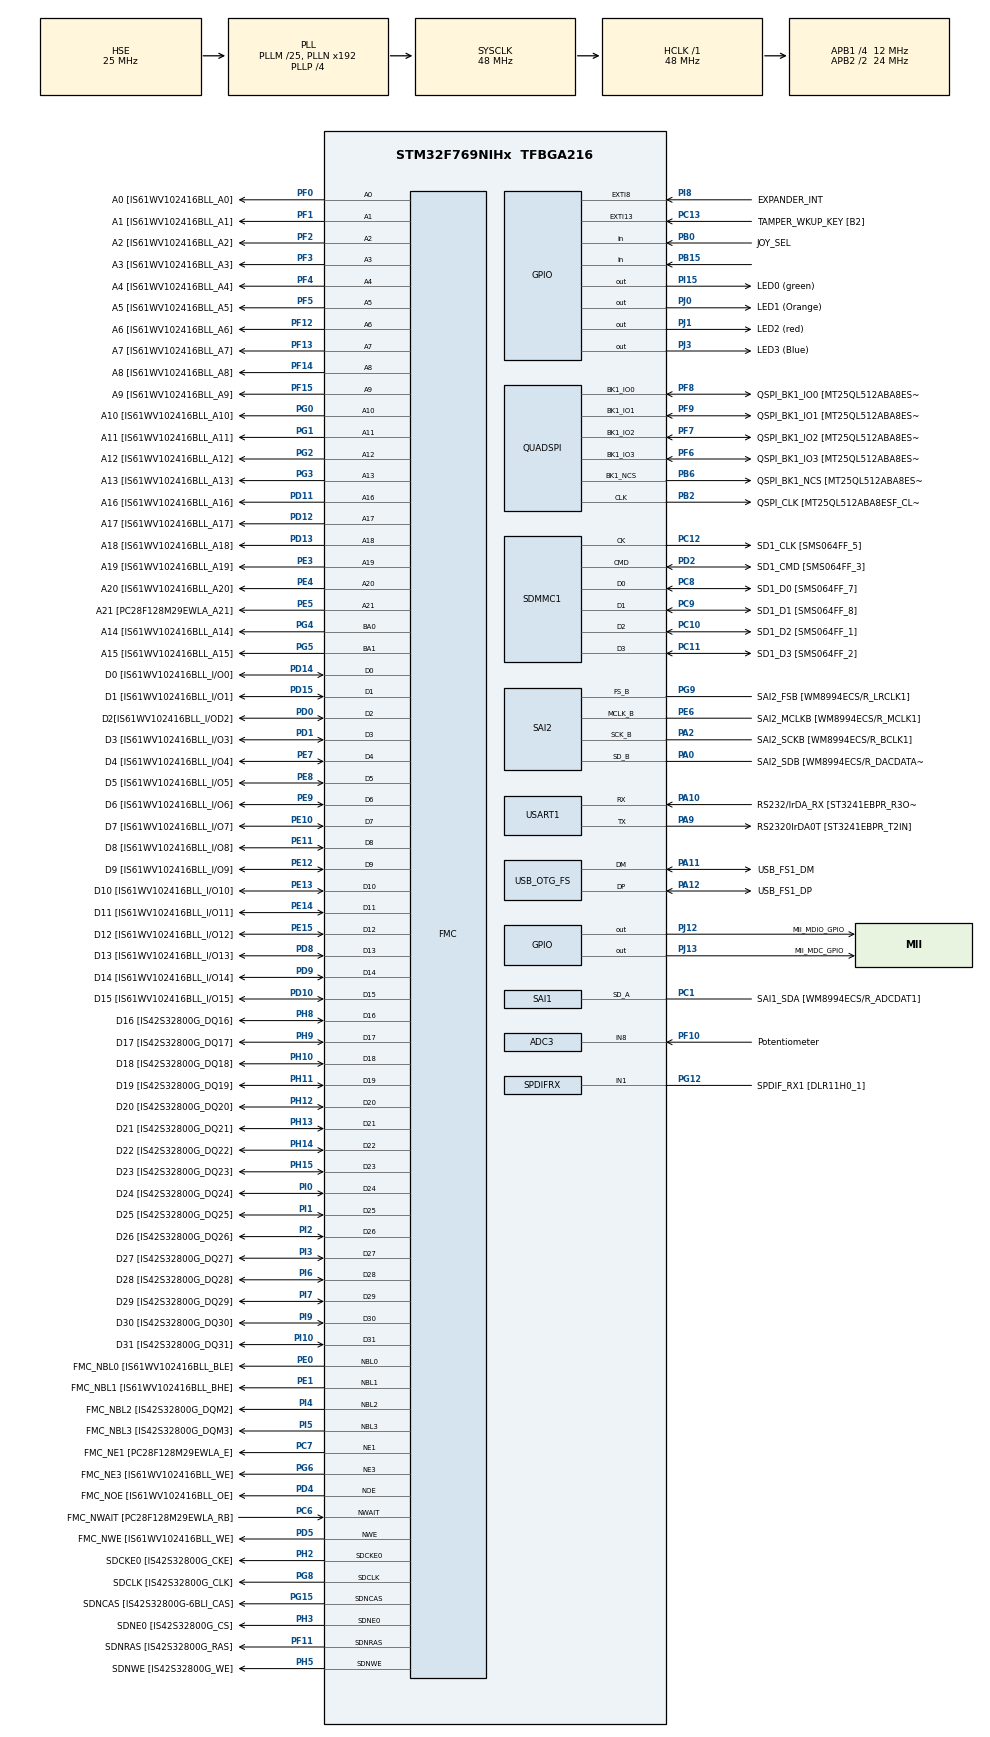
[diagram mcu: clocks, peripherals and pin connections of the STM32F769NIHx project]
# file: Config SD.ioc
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ADC3.Channel-0\#ChannelRegularConversion=ADC_CHANNEL_8
ADC3.NbrOfConversionFlag=1
ADC3.Rank-0\#ChannelRegularConversion=1
ADC3.SamplingTime-0\#ChannelRegularConversion=ADC_SAMPLETIME_3CYCLES
DSIHOST_CKN.GPIO_Label=DSI_CK_N
DSIHOST_CKN.Mode=DSIHost_Standalone
DSIHOST_CKN.Signal=DSIHOST_CKN
DSIHOST_CKP.GPIO_Label=DSI_CK_P
DSIHOST_CKP.Mode=DSIHost_Standalone
DSIHOST_CKP.Signal=DSIHOST_CKP
DSIHOST_D0N.GPIO_Label=DSI_D0_N
DSIHOST_D0N.Mode=DSIHost_Standalone
DSIHOST_D0N.Signal=DSIHOST_D0N
DSIHOST_D0P.GPIO_Label=DSI_D0_P
DSIHOST_D0P.Mode=DSIHost_Standalone
DSIHOST_D0P.Signal=DSIHOST_D0P
DSIHOST_D1N.GPIO_Label=DSI_D1_N
DSIHOST_D1N.Mode=DSIHost_Standalone
DSIHOST_D1N.Signal=DSIHOST_D1N
DSIHOST_D1P.GPIO_Label=DSI_D1_P
DSIHOST_D1P.Mode=DSIHost_Standalone
DSIHOST_D1P.Signal=DSIHOST_D1P
Dma.Request0=SDMMC1_RX
Dma.Request1=SDMMC1_TX
Dma.SDMMC1_RX.0.Direction=DMA_PERIPH_TO_MEMORY
Dma.SDMMC1_RX.0.FIFOMode=DMA_FIFOMODE_ENABLE
Dma.SDMMC1_RX.0.FIFOThreshold=DMA_FIFO_THRESHOLD_FULL
Dma.SDMMC1_RX.0.Instance=DMA2_Stream3
Dma.SDMMC1_RX.0.MemBurst=DMA_MBURST_INC4
Dma.SDMMC1_RX.0.MemDataAlignment=DMA_MDATAALIGN_WORD
Dma.SDMMC1_RX.0.MemInc=DMA_MINC_ENABLE
Dma.SDMMC1_RX.0.Mode=DMA_PFCTRL
Dma.SDMMC1_RX.0.PeriphBurst=DMA_PBURST_INC4
Dma.SDMMC1_RX.0.PeriphDataAlignment=DMA_PDATAALIGN_WORD
Dma.SDMMC1_RX.0.PeriphInc=DMA_PINC_DISABLE
Dma.SDMMC1_RX.0.Priority=DMA_PRIORITY_LOW
Dma.SDMMC1_TX.1.Direction=DMA_MEMORY_TO_PERIPH
Dma.SDMMC1_TX.1.FIFOMode=DMA_FIFOMODE_ENABLE
Dma.SDMMC1_TX.1.FIFOThreshold=DMA_FIFO_THRESHOLD_FULL
Dma.SDMMC1_TX.1.Instance=DMA2_Stream6
Dma.SDMMC1_TX.1.MemBurst=DMA_MBURST_INC4
Dma.SDMMC1_TX.1.MemDataAlignment=DMA_MDATAALIGN_WORD
Dma.SDMMC1_TX.1.MemInc=DMA_MINC_ENABLE
Dma.SDMMC1_TX.1.Mode=DMA_PFCTRL
Dma.SDMMC1_TX.1.PeriphBurst=DMA_PBURST_INC4
Dma.SDMMC1_TX.1.PeriphDataAlignment=DMA_PDATAALIGN_WORD
Dma.SDMMC1_TX.1.PeriphInc=DMA_PINC_DISABLE
Dma.SDMMC1_TX.1.Priority=DMA_PRIORITY_LOW
FATFS.BSP.number=1
FATFS.USE_DMA_CODE_SD=1
FATFS0.BSP.STBoard=false
FATFS0.BSP.api=Unknown
FATFS0.BSP.instance=PB15
FATFS0.BSP.ip=GPIO
FATFS0.BSP.mode=Input
FATFS0.BSP.name=Detect_SDIO
FATFS0.BSP.solution=PB15
Mcu.Family=STM32F7
Mcu.Name=STM32F769NIHx
Mcu.Package=TFBGA216
NVIC.DMA2_Stream3_IRQn=true\:0\:0\:false\:false\:true\:false\:true\:true
NVIC.DMA2_Stream6_IRQn=true\:0\:0\:false\:false\:true\:false\:true\:true
NVIC.PriorityGroup=NVIC_PRIORITYGROUP_4
NVIC.SDMMC1_IRQn=true\:0\:0\:false\:false\:true\:true\:true\:true
PA0/WKUP.GPIO_Label=SAI2_SDB [WM8994ECS/R_DACDATA1]
PA0/WKUP.Mode=SAI_B_MasterWithClock
PA0/WKUP.Signal=SAI2_SD_B
PA1.GPIO_Label=MII_RX_CLK [DP83848CVV_RX_CLK]
PA1.Signal=ETH_RX_CLK
PA10.GPIO_Label=RS232/IrDA_RX [ST3241EBPR_R3OUT]
PA10.Mode=Asynchronous
PA10.Signal=USART1_RX
PA11.GPIO_Label=USB_FS1_DM
PA11.Mode=Device_Only
PA11.Signal=USB_OTG_FS_DM
PA12.GPIO_Label=USB_FS1_DP
PA12.Mode=Device_Only
PA12.Signal=USB_OTG_FS_DP
PA13.GPIO_Label=TMS/SWDIO
PA13.Mode=Serial_Wire
PA13.Signal=SYS_JTMS-SWDIO
PA14.GPIO_Label=TCK/SWCLK
PA14.Mode=Serial_Wire
PA14.Signal=SYS_JTCK-SWCLK
PA15.GPIO_Label=TDI
PA15.Signal=SYS_JTDI
PA2.GPIO_Label=SAI2_SCKB [WM8994ECS/R_BCLK1]
PA2.Mode=SAI_B_MasterWithClock
PA2.Signal=SAI2_SCK_B
PA3.GPIO_Label=ULPI_D0 [USB3300-EZK_D0]
PA3.Signal=USB_OTG_HS_ULPI_D0
PA4.GPIO_Label=PAR_HSYNC
PA4.Signal=DCMI_HSYNC
PA5.GPIO_Label=ULPI_CK [USB3300-EZK_CLKOUT]
PA5.Signal=USB_OTG_HS_ULPI_CK
PA6.GPIO_Label=PAR_PCLK
PA6.Signal=DCMI_PIXCLK
PA7.GPIO_Label=MII_RX_DV [DP83848CVV_RX_DV]
PA7.Signal=ETH_RX_DV
PA8.GPIO_Label=MII_MCO [DP83848CVV_X1]
PA8.Signal=RCC_MCO_1
PA9.GPIO_Label=RS2320IrDA0T [ST3241EBPR_T2IN]
PA9.Mode=Asynchronous
PA9.Signal=USART1_TX
PB0.GPIO_Label=JOY_SEL
PB0.Signal=GPIO_Input
PB1.GPIO_Label=ULPI_D2 [USB3300-EZK_D2]
PB1.Signal=USB_OTG_HS_ULPI_D2
PB10.GPIO_Label=ULPI_D3 [USB3300-EZK_D3]
PB10.Signal=USB_OTG_HS_ULPI_D3
PB11.GPIO_Label=ULPI_D4 [USB3300-EZK_D4]
PB11.Signal=USB_OTG_HS_ULPI_D4
PB12.GPIO_Label=ULPI_D5 [USB3300-EZK_D5]
PB12.Signal=USB_OTG_HS_ULPI_D5
PB13.GPIO_Label=ULPI_D6 [USB3300-EZK_D6]
PB13.Signal=USB_OTG_HS_ULPI_D6
PB14.GPIO_Label=USB_FS2_DM
PB14.Signal=USB_OTG_HS_DM
PB15.Signal=GPIO_Input
PB2.GPIO_Label=QSPI_CLK [MT25QL512ABA8ESF_CLK]
PB2.Mode=Single Bank 1
PB2.Signal=QUADSPI_CLK
PB3.GPIO_Label=SD2_D2 [SMS064FF_1]
PB3.Signal=SDMMC2_D2
PB4.GPIO_Label=SD2_D3 [SMS064FF_2]
PB4.Signal=SDMMC2_D3
PB5.GPIO_Label=ULPI_D7 [USB3300-EZK_D7]
PB5.Signal=USB_OTG_HS_ULPI_D7
PB6.GPIO_Label=QSPI_BK1_NCS [MT25QL512ABA8ESF-0SIT_CS]
PB6.Mode=Single Bank 1
PB6.Signal=QUADSPI_BK1_NCS
PB7.GPIO_Label=PAR_VSYNC
PB7.Signal=DCMI_VSYNC
PB8.GPIO_Label=I2C1_SCL [WM8994ECS/R_SCLK]
PB8.Signal=I2C1_SCL
PB9.GPIO_Label=I2C1_SDA [WM8994ECS/R_SDA]
PB9.Signal=I2C1_SDA
PC0.GPIO_Label=ULPI_STP [USB3300-EZK_STP]
PC0.Signal=USB_OTG_HS_ULPI_STP
PC1.GPIO_Label=SAI1_SDA [WM8994ECS/R_ADCDAT1]
PC1.Mode=SAI_A_SPDIF
PC1.Signal=SAI1_SD_A
PC10.GPIO_Label=SD1_D2 [SMS064FF_1]
PC10.Mode=SD_4_bits_Wide_bus
PC10.Signal=SDMMC1_D2
PC11.GPIO_Label=SD1_D3 [SMS064FF_2]
PC11.Mode=SD_4_bits_Wide_bus
PC11.Signal=SDMMC1_D3
PC12.GPIO_Label=SD1_CLK [SMS064FF_5]
PC12.Mode=SD_4_bits_Wide_bus
PC12.Signal=SDMMC1_CK
PC13.GPIO_Label=TAMPER_WKUP_KEY [B2]
PC13.Signal=GPXTI13
PC14/OSC32_IN.GPIO_Label=OSC32_IN
PC14/OSC32_IN.Mode=LSE-External-Oscillator
PC14/OSC32_IN.Signal=RCC_OSC32_IN
PC15/OSC32_OUT.GPIO_Label=OSC32_OUT
PC15/OSC32_OUT.Mode=LSE-External-Oscillator
PC15/OSC32_OUT.Signal=RCC_OSC32_OUT
PC2.GPIO_Label=MII_TXD2 [DP83848CVV_TXD_2]
PC2.Signal=ETH_TXD2
PC3.GPIO_Label=MII_TX_CLK [DP83848CVV_TX_CLK]
PC3.Signal=ETH_TX_CLK
PC4.GPIO_Label=MII_RXD0 [DP83848CVV_RXD_0/PHYAD1]
PC4.Signal=ETH_RXD0
PC5.GPIO_Label=MII_RXD1 [DP83848CVV_RXD_1/PHYAD2]
PC5.Signal=ETH_RXD1
PC6.GPIO_Label=FMC_NWAIT [PC28F128M29EWLA_RB]
PC6.Signal=FMC_NWAIT
PC7.GPIO_Label=FMC_NE1 [PC28F128M29EWLA_E]
PC7.Mode=NorPsramChipSelect1_1
PC7.Signal=FMC_NE1
PC8.GPIO_Label=SD1_D0 [SMS064FF_7]
PC8.Mode=SD_4_bits_Wide_bus
PC8.Signal=SDMMC1_D0
PC9.GPIO_Label=SD1_D1 [SMS064FF_8]
PC9.Mode=SD_4_bits_Wide_bus
PC9.Signal=SDMMC1_D1
PD0.GPIO_Label=D2[IS61WV102416BLL_I/OD2]
PD0.Signal=FMC_D2_DA2
PD1.GPIO_Label=D3 [IS61WV102416BLL_I/O3]
PD1.Signal=FMC_D3_DA3
PD10.GPIO_Label=D15 [IS61WV102416BLL_I/O15]
PD10.Signal=FMC_D15_DA15
PD11.GPIO_Label=A16 [IS61WV102416BLL_A16]
PD11.Signal=FMC_A16_CLE
PD12.GPIO_Label=A17 [IS61WV102416BLL_A17]
PD12.Signal=FMC_A17_ALE
PD13.GPIO_Label=A18 [IS61WV102416BLL_A18]
PD13.Signal=FMC_A18
PD14.GPIO_Label=D0 [IS61WV102416BLL_I/O0]
PD14.Signal=FMC_D0_DA0
PD15.GPIO_Label=D1 [IS61WV102416BLL_I/O1]
PD15.Signal=FMC_D1_DA1
PD2.GPIO_Label=SD1_CMD [SMS064FF_3]
PD2.Mode=SD_4_bits_Wide_bus
PD2.Signal=SDMMC1_CMD
PD3.GPIO_Label=PAR_D5
PD3.Signal=DCMI_D5
PD4.GPIO_Label=FMC_NOE [IS61WV102416BLL_OE]
PD4.Signal=FMC_NOE
PD5.GPIO_Label=FMC_NWE [IS61WV102416BLL_WE]
PD5.Signal=FMC_NWE
PD6.GPIO_Label=SD2_CLK [SMS064FF_5]
PD6.Signal=SDMMC2_CK
PD7.GPIO_Label=SD2_CMD [SMS064FF_3]
PD7.Signal=SDMMC2_CMD
PD8.GPIO_Label=D13 [IS61WV102416BLL_I/O13]
PD8.Signal=FMC_D13_DA13
PD9.GPIO_Label=D14 [IS61WV102416BLL_I/O14]
PD9.Signal=FMC_D14_DA14
PE0.GPIO_Label=FMC_NBL0 [IS61WV102416BLL_BLE]
PE0.Signal=FMC_NBL0
PE1.GPIO_Label=FMC_NBL1 [IS61WV102416BLL_BHE]
PE1.Signal=FMC_NBL1
PE10.GPIO_Label=D7 [IS61WV102416BLL_I/O7]
PE10.Signal=FMC_D7_DA7
PE11.GPIO_Label=D8 [IS61WV102416BLL_I/O8]
PE11.Signal=FMC_D8_DA8
PE12.GPIO_Label=D9 [IS61WV102416BLL_I/O9]
PE12.Signal=FMC_D9_DA9
PE13.GPIO_Label=D10 [IS61WV102416BLL_I/O10]
PE13.Signal=FMC_D10_DA10
PE14.GPIO_Label=D11 [IS61WV102416BLL_I/O11]
PE14.Signal=FMC_D11_DA11
PE15.GPIO_Label=D12 [IS61WV102416BLL_I/O12]
PE15.Signal=FMC_D12_DA12
PE2.GPIO_Label=MII_TXD3 [DP83848CVV_TXD_3]
PE2.Signal=ETH_TXD3
PE3.GPIO_Label=A19 [IS61WV102416BLL_A19]
PE3.Signal=FMC_A19
PE4.GPIO_Label=A20 [IS61WV102416BLL_A20]
PE4.Signal=FMC_A20
PE5.GPIO_Label=A21 [PC28F128M29EWLA_A21]
PE5.Signal=FMC_A21
PE6.GPIO_Label=SAI2_MCLKB [WM8994ECS/R_MCLK1]
PE6.Mode=SAI_B_MasterWithClock
PE6.Signal=SAI2_MCLK_B
PE7.GPIO_Label=D4 [IS61WV102416BLL_I/O4]
PE7.Signal=FMC_D4_DA4
PE8.GPIO_Label=D5 [IS61WV102416BLL_I/O5]
PE8.Signal=FMC_D5_DA5
PE9.GPIO_Label=D6 [IS61WV102416BLL_I/O6]
PE9.Signal=FMC_D6_DA6
PF0.GPIO_Label=A0 [IS61WV102416BLL_A0]
PF0.Signal=FMC_A0
PF1.GPIO_Label=A1 [IS61WV102416BLL_A1]
PF1.Signal=FMC_A1
PF10.GPIO_Label=Potentiometer
PF10.Mode=IN8
PF10.Signal=ADC3_IN8
PF11.GPIO_Label=SDNRAS [IS42S32800G_RAS]
PF11.Signal=FMC_SDNRAS
PF12.GPIO_Label=A6 [IS61WV102416BLL_A6]
PF12.Signal=FMC_A6
PF13.GPIO_Label=A7 [IS61WV102416BLL_A7]
PF13.Signal=FMC_A7
PF14.GPIO_Label=A8 [IS61WV102416BLL_A8]
PF14.Signal=FMC_A8
PF15.GPIO_Label=A9 [IS61WV102416BLL_A9]
PF15.Signal=FMC_A9
PF2.GPIO_Label=A2 [IS61WV102416BLL_A2]
PF2.Signal=FMC_A2
PF3.GPIO_Label=A3 [IS61WV102416BLL_A3]
PF3.Signal=FMC_A3
PF4.GPIO_Label=A4 [IS61WV102416BLL_A4]
PF4.Signal=FMC_A4
PF5.GPIO_Label=A5 [IS61WV102416BLL_A5]
PF5.Signal=FMC_A5
PF6.GPIO_Label=QSPI_BK1_IO3 [MT25QL512ABA8ESF_HOLD\#/DQ3]
PF6.Mode=Single Bank 1
PF6.Signal=QUADSPI_BK1_IO3
PF7.GPIO_Label=QSPI_BK1_IO2 [MT25QL512ABA8ESF_W\#/Vpp/DQ2]
PF7.Mode=Single Bank 1
PF7.Signal=QUADSPI_BK1_IO2
PF8.GPIO_Label=QSPI_BK1_IO0 [MT25QL512ABA8ESF_DQ0]
PF8.Mode=Single Bank 1
PF8.Signal=QUADSPI_BK1_IO0
PF9.GPIO_Label=QSPI_BK1_IO1 [MT25QL512ABA8ESF_DQ1]
PF9.Mode=Single Bank 1
PF9.Signal=QUADSPI_BK1_IO1
PG0.GPIO_Label=A10 [IS61WV102416BLL_A10]
PG0.Signal=FMC_A10
PG1.GPIO_Label=A11 [IS61WV102416BLL_A11]
PG1.Signal=FMC_A11
PG10.GPIO_Label=SD2_D1 [SMS064FF_8]
PG10.Signal=SDMMC2_D1
PG11.GPIO_Label=MII_TX_EN [DP83848CVV_TX_EN]
PG11.Signal=ETH_TX_EN
PG12.GPIO_Label=SPDIF_RX1 [DLR11H0_1]
PG12.Mode=IN1
PG12.Signal=SPDIFRX_IN1
PG13.GPIO_Label=MII_TXD0 [DP83848CVV_TXD0]
PG13.Signal=ETH_TXD0
PG14.GPIO_Label=MII_TXD1 [DP83848CVV_TXD1]
PG14.Signal=ETH_TXD1
PG15.GPIO_Label=SDNCAS [IS42S32800G-6BLI_CAS]
PG15.Signal=FMC_SDNCAS
PG2.GPIO_Label=A12 [IS61WV102416BLL_A12]
PG2.Signal=FMC_A12
PG3.GPIO_Label=A13 [IS61WV102416BLL_A13]
PG3.Signal=FMC_A13
PG4.GPIO_Label=A14 [IS61WV102416BLL_A14]
PG4.Signal=FMC_A14_BA0
PG5.GPIO_Label=A15 [IS61WV102416BLL_A15]
PG5.Signal=FMC_A15_BA1
PG6.GPIO_Label=FMC_NE3 [IS61WV102416BLL_WE]
PG6.Mode=NorPsramChipSelect3_2
PG6.Signal=FMC_NE3
PG7.GPIO_Label=NAND_INT
PG7.Signal=FMC_INT
PG8.GPIO_Label=SDCLK [IS42S32800G_CLK]
PG8.Signal=FMC_SDCLK
PG9.GPIO_Label=SAI2_FSB [WM8994ECS/R_LRCLK1]
PG9.Mode=SAI_B_MasterWithClock
PG9.Signal=SAI2_FS_B
PH0/OSC_IN.GPIO_Label=OSC_IN
PH0/OSC_IN.Mode=HSE-External-Oscillator
PH0/OSC_IN.Signal=RCC_OSC_IN
PH1/OSC_OUT.GPIO_Label=OSC_OUT
PH1/OSC_OUT.Mode=HSE-External-Oscillator
PH1/OSC_OUT.Signal=RCC_OSC_OUT
PH10.GPIO_Label=D18 [IS42S32800G_DQ18]
PH10.Signal=FMC_D18
PH11.GPIO_Label=D19 [IS42S32800G_DQ19]
PH11.Signal=FMC_D19
PH12.GPIO_Label=D20 [IS42S32800G_DQ20]
PH12.Signal=FMC_D20
PH13.GPIO_Label=D21 [IS42S32800G_DQ21]
PH13.Signal=FMC_D21
PH14.GPIO_Label=D22 [IS42S32800G_DQ22]
PH14.Signal=FMC_D22
PH15.GPIO_Label=D23 [IS42S32800G_DQ23]
PH15.Signal=FMC_D23
PH2.GPIO_Label=SDCKE0 [IS42S32800G_CKE]
PH2.Mode=SdramChipSelect1_1
PH2.Signal=FMC_SDCKE0
PH3.GPIO_Label=SDNE0 [IS42S32800G_CS]
PH3.Mode=SdramChipSelect1_1
PH3.Signal=FMC_SDNE0
PH4.GPIO_Label=ULPI_NXT [USB3300-EZK_NXT]
PH4.Signal=USB_OTG_HS_ULPI_NXT
PH5.GPIO_Label=SDNWE [IS42S32800G_WE]
PH5.Signal=FMC_SDNWE
PH6.GPIO_Label=MII_RXD2 [DP83848CVV_RXD_2/PHYAD3]
PH6.Signal=ETH_RXD2
PH7.GPIO_Label=MII_RXD3 [DP83848CVV_RXD_3/PHYAD4]
PH7.Signal=ETH_RXD3
PH8.GPIO_Label=D16 [IS42S32800G_DQ16]
PH8.Signal=FMC_D16
PH9.GPIO_Label=D17 [IS42S32800G_DQ17]
PH9.Signal=FMC_D17
PI0.GPIO_Label=D24 [IS42S32800G_DQ24]
PI0.Signal=FMC_D24
PI1.GPIO_Label=D25 [IS42S32800G_DQ25]
PI1.Signal=FMC_D25
PI10.GPIO_Label=D31 [IS42S32800G_DQ31]
PI10.Signal=FMC_D31
PI11.GPIO_Label=ULPI_DIR [USB3300_DIR]
PI11.Signal=USB_OTG_HS_ULPI_DIR
PI12.GPIO_Label=LCD_HSYNC
PI12.Signal=LTDC_HSYNC
PI13.GPIO_Label=LCD_VSYNC
PI13.Signal=LTDC_VSYNC
PI14.GPIO_Label=LCD_CLK
PI14.Signal=LTDC_CLK
PI15.GPIO_Label=LED0 (green)
PI15.Signal=GPIO_Output
PI2.GPIO_Label=D26 [IS42S32800G_DQ26]
PI2.Signal=FMC_D26
PI3.GPIO_Label=D27 [IS42S32800G_DQ27]
PI3.Signal=FMC_D27
PI4.GPIO_Label=FMC_NBL2 [IS42S32800G_DQM2]
PI4.Signal=FMC_NBL2
PI5.GPIO_Label=FMC_NBL3 [IS42S32800G_DQM3]
PI5.Signal=FMC_NBL3
PI6.GPIO_Label=D28 [IS42S32800G_DQ28]
PI6.Signal=FMC_D28
PI7.GPIO_Label=D29 [IS42S32800G_DQ29]
PI7.Signal=FMC_D29
PI8.GPIO_Label=EXPANDER_INT
PI8.Signal=GPXTI8
PI9.GPIO_Label=D30 [IS42S32800G_DQ30]
PI9.Signal=FMC_D30
PJ0.GPIO_Label=LED1 (Orange)
PJ0.Signal=GPIO_Output
PJ1.GPIO_Label=LED2 (red)
PJ1.Signal=GPIO_Output
PJ12.GPIO_Label=MII_MDIO_GPIO
PJ12.Signal=GPIO_Output
PJ13.GPIO_Label=MII_MDC_GPIO
PJ13.Signal=GPIO_Output
PJ14.GPIO_Label=LCD_B2
PJ14.Signal=LTDC_B2
PJ15.GPIO_Label=LCD_B3
PJ15.Signal=LTDC_B3
PJ2.GPIO_Label=DSI_TE
PJ2.Signal=DSIHOST_TE
PJ3.GPIO_Label=LED3 (Blue)
PJ3.Signal=GPIO_Output
PJ4.GPIO_Label=LCD_R5
PJ4.Signal=LTDC_R5
PJ5.GPIO_Label=LCD_R6
PJ5.Signal=LTDC_R6
PK3.GPIO_Label=LCD_B4
PK3.Signal=LTDC_B4
PK4.GPIO_Label=LCD_B5
PK4.Signal=LTDC_B5
PK5.GPIO_Label=LCD_B6
PK5.Signal=LTDC_B6
PK6.GPIO_Label=LCD_B7
PK6.Signal=LTDC_B7
PK7.GPIO_Label=LCD_DE
PK7.Signal=LTDC_DE
ProjectManager.HeapSize=0x400
ProjectManager.StackSize=0x800
ProjectManager.TargetToolchain=STM32CubeIDE
QUADSPI.ChipSelectHighTime=QSPI_CS_HIGH_TIME_6_CYCLE
QUADSPI.ClockPrescaler=1
QUADSPI.FifoThreshold=4
QUADSPI.FlashSize=26
QUADSPI.SampleShifting=QSPI_SAMPLE_SHIFTING_HALFCYCLE
RCC.AHBFreq_Value=48000000
RCC.APB1CLKDivider=RCC_HCLK_DIV4
RCC.APB1Freq_Value=12000000
RCC.APB1TimFreq_Value=24000000
RCC.APB2CLKDivider=RCC_HCLK_DIV2
RCC.APB2Freq_Value=24000000
RCC.APB2TimFreq_Value=48000000
RCC.CortexFreq_Value=48000000
RCC.HCLKFreq_Value=48000000
RCC.HSE_VALUE=25000000
RCC.HSI_VALUE=16000000
RCC.PLLM=25
RCC.PLLP=RCC_PLLP_DIV4
RCC.PLLQ=4
RCC.PLLSAIQ=3
RCC.SDMMCClockSelection=RCC_SDMMC1CLKSOURCE_CLK48
RCC.SYSCLKFreq_VALUE=48000000
RCC.SYSCLKSource=RCC_SYSCLKSOURCE_PLLCLK
RCC.USBFreq_Value=48000000
RCC.VCOOutputFreq_Value=192000000
SAI1.Instance-SAI_A_SPDIF=SAI$Index_Block_A
SAI1.VirtualMode-SAI_A_SPDIF=VM_SPDIF
SAI2.Instance-SAI_B_MasterWithClock=SAI$Index_Block_B
SAI2.MClockEnable-SAI_B_MasterWithClock=SAI_MASTERCLOCK_ENABLE
SAI2.VirtualMode-SAI_B_MasterWithClock=VM_MASTER
SH.FMC_A0.0=FMC_A0,13b-sda1
SH.FMC_A0.1=FMC_A0,22b-a1
SH.FMC_A0.2=FMC_A0,22b-a2
SH.FMC_A1.0=FMC_A1,13b-sda1
SH.FMC_A1.1=FMC_A1,22b-a1
SH.FMC_A1.2=FMC_A1,22b-a2
SH.FMC_A10.0=FMC_A10,13b-sda1
SH.FMC_A10.1=FMC_A10,22b-a1
SH.FMC_A10.2=FMC_A10,22b-a2
SH.FMC_A11.0=FMC_A11,13b-sda1
SH.FMC_A11.1=FMC_A11,22b-a1
SH.FMC_A11.2=FMC_A11,22b-a2
SH.FMC_A12.0=FMC_A12,13b-sda1
SH.FMC_A12.1=FMC_A12,22b-a1
SH.FMC_A12.2=FMC_A12,22b-a2
SH.FMC_A13.0=FMC_A13,22b-a1
SH.FMC_A13.1=FMC_A13,22b-a2
SH.FMC_A14_BA0.0=FMC_BA0,FourSdramBanks1
SH.FMC_A14_BA0.1=FMC_A14,22b-a1
SH.FMC_A14_BA0.2=FMC_A14,22b-a2
SH.FMC_A15_BA1.0=FMC_BA1,FourSdramBanks1
SH.FMC_A15_BA1.1=FMC_A15,22b-a1
SH.FMC_A15_BA1.2=FMC_A15,22b-a2
SH.FMC_A16_CLE.0=FMC_A16,22b-a1
SH.FMC_A16_CLE.1=FMC_A16,22b-a2
SH.FMC_A17_ALE.0=FMC_A17,22b-a1
SH.FMC_A17_ALE.1=FMC_A17,22b-a2
SH.FMC_A18.0=FMC_A18,22b-a1
SH.FMC_A18.1=FMC_A18,22b-a2
SH.FMC_A19.0=FMC_A19,22b-a1
SH.FMC_A19.1=FMC_A19,22b-a2
SH.FMC_A2.0=FMC_A2,13b-sda1
SH.FMC_A2.1=FMC_A2,22b-a1
SH.FMC_A2.2=FMC_A2,22b-a2
SH.FMC_A20.0=FMC_A20,22b-a1
SH.FMC_A20.1=FMC_A20,22b-a2
SH.FMC_A21.0=FMC_A21,22b-a1
SH.FMC_A21.1=FMC_A21,22b-a2
SH.FMC_A3.0=FMC_A3,13b-sda1
SH.FMC_A3.1=FMC_A3,22b-a1
SH.FMC_A3.2=FMC_A3,22b-a2
SH.FMC_A4.0=FMC_A4,13b-sda1
SH.FMC_A4.1=FMC_A4,22b-a1
SH.FMC_A4.2=FMC_A4,22b-a2
SH.FMC_A5.0=FMC_A5,13b-sda1
SH.FMC_A5.1=FMC_A5,22b-a1
SH.FMC_A5.2=FMC_A5,22b-a2
SH.FMC_A6.0=FMC_A6,13b-sda1
SH.FMC_A6.1=FMC_A6,22b-a1
SH.FMC_A6.2=FMC_A6,22b-a2
SH.FMC_A7.0=FMC_A7,13b-sda1
SH.FMC_A7.1=FMC_A7,22b-a1
SH.FMC_A7.2=FMC_A7,22b-a2
SH.FMC_A8.0=FMC_A8,13b-sda1
SH.FMC_A8.1=FMC_A8,22b-a1
SH.FMC_A8.2=FMC_A8,22b-a2
SH.FMC_A9.0=FMC_A9,13b-sda1
SH.FMC_A9.1=FMC_A9,22b-a1
SH.FMC_A9.2=FMC_A9,22b-a2
SH.FMC_D0_DA0.0=FMC_D0,16b-d1
SH.FMC_D0_DA0.1=FMC_D0,16b-d2
SH.FMC_D0_DA0.2=FMC_D0,sd-32b-d1
SH.FMC_D10_DA10.0=FMC_D10,16b-d1
SH.FMC_D10_DA10.1=FMC_D10,16b-d2
SH.FMC_D10_DA10.2=FMC_D10,sd-32b-d1
SH.FMC_D11_DA11.0=FMC_D11,16b-d1
SH.FMC_D11_DA11.1=FMC_D11,16b-d2
SH.FMC_D11_DA11.2=FMC_D11,sd-32b-d1
SH.FMC_D12_DA12.0=FMC_D12,16b-d1
SH.FMC_D12_DA12.1=FMC_D12,16b-d2
SH.FMC_D12_DA12.2=FMC_D12,sd-32b-d1
SH.FMC_D13_DA13.0=FMC_D13,16b-d1
SH.FMC_D13_DA13.1=FMC_D13,16b-d2
SH.FMC_D13_DA13.2=FMC_D13,sd-32b-d1
SH.FMC_D14_DA14.0=FMC_D14,16b-d1
SH.FMC_D14_DA14.1=FMC_D14,16b-d2
SH.FMC_D14_DA14.2=FMC_D14,sd-32b-d1
SH.FMC_D15_DA15.0=FMC_D15,16b-d1
SH.FMC_D15_DA15.1=FMC_D15,16b-d2
SH.FMC_D15_DA15.2=FMC_D15,sd-32b-d1
SH.FMC_D16.0=FMC_D16,sd-32b-d1
SH.FMC_D17.0=FMC_D17,sd-32b-d1
SH.FMC_D18.0=FMC_D18,sd-32b-d1
SH.FMC_D19.0=FMC_D19,sd-32b-d1
SH.FMC_D1_DA1.0=FMC_D1,16b-d1
SH.FMC_D1_DA1.1=FMC_D1,16b-d2
SH.FMC_D1_DA1.2=FMC_D1,sd-32b-d1
SH.FMC_D20.0=FMC_D20,sd-32b-d1
SH.FMC_D21.0=FMC_D21,sd-32b-d1
SH.FMC_D22.0=FMC_D22,sd-32b-d1
SH.FMC_D23.0=FMC_D23,sd-32b-d1
SH.FMC_D24.0=FMC_D24,sd-32b-d1
SH.FMC_D25.0=FMC_D25,sd-32b-d1
SH.FMC_D26.0=FMC_D26,sd-32b-d1
SH.FMC_D27.0=FMC_D27,sd-32b-d1
SH.FMC_D28.0=FMC_D28,sd-32b-d1
SH.FMC_D29.0=FMC_D29,sd-32b-d1
SH.FMC_D2_DA2.0=FMC_D2,16b-d1
SH.FMC_D2_DA2.1=FMC_D2,16b-d2
SH.FMC_D2_DA2.2=FMC_D2,sd-32b-d1
SH.FMC_D30.0=FMC_D30,sd-32b-d1
SH.FMC_D31.0=FMC_D31,sd-32b-d1
SH.FMC_D3_DA3.0=FMC_D3,16b-d1
SH.FMC_D3_DA3.1=FMC_D3,16b-d2
SH.FMC_D3_DA3.2=FMC_D3,sd-32b-d1
SH.FMC_D4_DA4.0=FMC_D4,16b-d1
SH.FMC_D4_DA4.1=FMC_D4,16b-d2
SH.FMC_D4_DA4.2=FMC_D4,sd-32b-d1
SH.FMC_D5_DA5.0=FMC_D5,16b-d1
SH.FMC_D5_DA5.1=FMC_D5,16b-d2
SH.FMC_D5_DA5.2=FMC_D5,sd-32b-d1
SH.FMC_D6_DA6.0=FMC_D6,16b-d1
SH.FMC_D6_DA6.1=FMC_D6,16b-d2
SH.FMC_D6_DA6.2=FMC_D6,sd-32b-d1
SH.FMC_D7_DA7.0=FMC_D7,16b-d1
SH.FMC_D7_DA7.1=FMC_D7,16b-d2
SH.FMC_D7_DA7.2=FMC_D7,sd-32b-d1
SH.FMC_D8_DA8.0=FMC_D8,16b-d1
SH.FMC_D8_DA8.1=FMC_D8,16b-d2
SH.FMC_D8_DA8.2=FMC_D8,sd-32b-d1
SH.FMC_D9_DA9.0=FMC_D9,16b-d1
SH.FMC_D9_DA9.1=FMC_D9,16b-d2
SH.FMC_D9_DA9.2=FMC_D9,sd-32b-d1
SH.FMC_INT.0=FMC_INT
SH.FMC_NBL0.0=FMC_NBL0,2ByteEnable2
SH.FMC_NBL0.1=FMC_NBL0,Sd4ByteEnable1
SH.FMC_NBL1.0=FMC_NBL1,2ByteEnable2
SH.FMC_NBL1.1=FMC_NBL1,Sd4ByteEnable1
SH.FMC_NBL2.0=FMC_NBL2,Sd4ByteEnable1
SH.FMC_NBL3.0=FMC_NBL3,Sd4ByteEnable1
SH.FMC_NOE.0=FMC_NOE,NorFlash1
SH.FMC_NOE.1=FMC_NOE,Sram2
SH.FMC_NWAIT.0=FMC_NWAIT,AsynchronousWait1
SH.FMC_NWAIT.1=FMC_NWAIT,AsynchronousWait2
SH.FMC_NWE.0=FMC_NWE,NorFlash1
SH.FMC_NWE.1=FMC_NWE,Sram2
SH.FMC_SDCLK.0=FMC_SDCLK,13b-sda1
SH.FMC_SDNCAS.0=FMC_SDNCAS,13b-sda1
SH.FMC_SDNRAS.0=FMC_SDNRAS,13b-sda1
SH.FMC_SDNWE.0=FMC_SDNWE,13b-sda1
USART1.VirtualMode-Asynchronous=VM_ASYNC
USB_OTG_FS.VirtualMode=Device_Only
VP_FATFS_VS_SDIO.Mode=SDIO
VP_RTC_VS_RTC_Activate.Mode=RTC_Enabled
VP_RTC_VS_RTC_Calendar.Mode=RTC_Calendar
board=STM32F769I-EVAL

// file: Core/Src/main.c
/* USER CODE BEGIN Header */
/**
  ******************************************************************************
  * @file           : main.c
  * @brief          : Main program body
  ******************************************************************************
  * @attention
  *
  * Copyright (c) 2022 STMicroelectronics.
  * All rights reserved.
  *
  * This software is licensed under terms that can be found in the LICENSE file
  * in the root directory of this software component.
  * If no LICENSE file comes with this software, it is provided AS-IS.
  *
  ******************************************************************************
  */
/* USER CODE END Header */
#include "main.h"
#include "fatfs.h"

/* USER CODE BEGIN Includes */
#include <stdio.h>
//define flag rtc
#define SET_TIME_RTC 0
//string to date config

/* USER CODE END Includes */

ADC_HandleTypeDef hadc3;

DSI_HandleTypeDef hdsi;

QSPI_HandleTypeDef hqspi;

RTC_HandleTypeDef hrtc;

SAI_HandleTypeDef hsai_BlockA1;
SAI_HandleTypeDef hsai_BlockB2;

SD_HandleTypeDef hsd1;
DMA_HandleTypeDef hdma_sdmmc1_rx;
DMA_HandleTypeDef hdma_sdmmc1_tx;

SPDIFRX_HandleTypeDef hspdif;

UART_HandleTypeDef huart1;

PCD_HandleTypeDef hpcd_USB_OTG_FS;

NOR_HandleTypeDef hnor1;
SRAM_HandleTypeDef hsram2;
SDRAM_HandleTypeDef hsdram1;

void SystemClock_Config(void);
void PeriphCommonClock_Config(void);
static void MX_GPIO_Init(void);
static void MX_ADC3_Init(void);
static void MX_DSIHOST_DSI_Init(void);
static void MX_FMC_Init(void);
static void MX_QUADSPI_Init(void);
static void MX_SAI1_Init(void);
static void MX_SAI2_Init(void);
static void MX_SDMMC1_SD_Init(void);
static void MX_SPDIFRX_Init(void);
static void MX_USART1_UART_Init(void);
static void MX_USB_OTG_FS_PCD_Init(void);
static void MX_DMA_Init(void);
static void MX_RTC_Init(void);

/* USER CODE BEGIN 0 */
char* time, date;

void get_time(void)
{
 RTC_DateTypeDef gDate;
 RTC_TimeTypeDef gTime;
/* Get the RTC current Time */
 HAL_RTC_GetTime(&hrtc, &gTime, RTC_FORMAT_BIN);
/* Get the RTC current Date */
 HAL_RTC_GetDate(&hrtc, &gDate, RTC_FORMAT_BIN);
/* Display time Format: hh:mm:ss */
 sprintf((char*)time,"%02d:%02d:%02d",gTime.Hours, gTime.Minutes, gTime.Seconds);
/* Display date Format: dd-mm-yy */
 sprintf((char*)date,"%02d-%02d-%4d",gDate.Date, gDate.Month, 2000 + gDate.Year);

}
/* USER CODE END 0 */

int main(void)
{
  /* USER CODE BEGIN 1 */
  FRESULT res; /* FatFs function common result code */
  uint32_t byteswritten, bytesread; /* File write/read counts */
  uint8_t wtext[] = "STM32 FATFS works great!"; /* File write buffer */
  uint8_t rtext[_MAX_SS];/* File read buffer */

  /* USER CODE END 1 */

  /* MCU Configuration--------------------------------------------------------*/

  /* Reset of all peripherals, Initializes the Flash interface and the Systick. */
  HAL_Init();

  /* Configure the system clock */
  SystemClock_Config();

/* Configure the peripherals common clocks */
  PeriphCommonClock_Config();

  /* Initialize all configured peripherals */
  MX_GPIO_Init();
  MX_ADC3_Init();
  MX_DSIHOST_DSI_Init();
  MX_FMC_Init();
  MX_QUADSPI_Init();
  MX_SAI1_Init();
  MX_SAI2_Init();
  MX_SDMMC1_SD_Init();
  MX_SPDIFRX_Init();
  MX_USART1_UART_Init();
  MX_USB_OTG_FS_PCD_Init();
  MX_DMA_Init();
  MX_RTC_Init();
  MX_FATFS_Init();
  /* USER CODE BEGIN 2 */
  HAL_GPIO_WritePin(LED0_GPIO_Port, LED0_Pin, GPIO_PIN_SET);
  HAL_GPIO_WritePin(LED1_GPIO_Port, LED1_Pin, GPIO_PIN_SET);
  HAL_GPIO_WritePin(LED2_GPIO_Port, LED2_Pin, GPIO_PIN_SET);
  HAL_GPIO_WritePin(LED3_GPIO_Port, LED3_Pin, GPIO_PIN_SET);
  if(f_mount(&SDFatFS, (TCHAR const*)SDPath, 0) != FR_OK)
      {
	  HAL_GPIO_TogglePin(LED2_GPIO_Port, LED3_Pin);
          Error_Handler();
      }
      else
      {
          if(f_mkfs((TCHAR const*)SDPath, FM_ANY, 0, rtext, sizeof(rtext)) != FR_OK)
          {
        	  HAL_GPIO_TogglePin(LED2_GPIO_Port, LED3_Pin);
              Error_Handler();
          }
          else
          {
              //Open file for writing (Create)
              if(f_open(&SDFile, "STM32.TXT", FA_CREATE_ALWAYS | FA_WRITE) != FR_OK)
              {
            	  HAL_GPIO_TogglePin(LED2_GPIO_Port, LED3_Pin);
                  Error_Handler();
              }
              else
              {

                  //Write to the text file
                  res = f_write(&SDFile, time, strlen((char *)time), (void *)&byteswritten);
                  if((byteswritten == 0) || (res != FR_OK))
                  {
                	  HAL_GPIO_TogglePin(LED2_GPIO_Port, LED3_Pin);
                      Error_Handler();
                  }
                  else
                  {

                      f_close(&SDFile);
                  }
              }
          }
      }
      f_mount(&SDFatFS, (TCHAR const*)NULL, 0);

  /* USER CODE END 2 */

  /* Infinite loop */
  while (1)
  {

    /* USER CODE BEGIN 3 */
	  HAL_GPIO_TogglePin(LED2_GPIO_Port, LED2_Pin);
	  HAL_Delay(1000);
	  get_time();
	  if (HAL_GPIO_ReadPin(JOY_SEL_GPIO_Port, JOY_SEL_Pin) == 1)
		  HAL_GPIO_WritePin(LED0_GPIO_Port, LED0_Pin, GPIO_PIN_SET);
	  else
	  {
		  HAL_GPIO_WritePin(LED0_GPIO_Port, LED0_Pin, GPIO_PIN_RESET);
	  }
  }
  /* USER CODE END 3 */
}

void SystemClock_Config(void)
{
  RCC_OscInitTypeDef RCC_OscInitStruct = {0};
  RCC_ClkInitTypeDef RCC_ClkInitStruct = {0};

  /** Configure LSE Drive Capability
  */
  HAL_PWR_EnableBkUpAccess();

  /** Configure the main internal regulator output voltage
  */
  __HAL_RCC_PWR_CLK_ENABLE();
  __HAL_PWR_VOLTAGESCALING_CONFIG(PWR_REGULATOR_VOLTAGE_SCALE3);

  /** Initializes the RCC Oscillators according to the specified parameters
  * in the RCC_OscInitTypeDef structure.
  */
  RCC_OscInitStruct.OscillatorType = RCC_OSCILLATORTYPE_LSI|RCC_OSCILLATORTYPE_HSE;
  RCC_OscInitStruct.HSEState = RCC_HSE_ON;
  RCC_OscInitStruct.LSIState = RCC_LSI_ON;
  RCC_OscInitStruct.PLL.PLLState = RCC_PLL_ON;
  RCC_OscInitStruct.PLL.PLLSource = RCC_PLLSOURCE_HSE;
  RCC_OscInitStruct.PLL.PLLM = 25;
  RCC_OscInitStruct.PLL.PLLN = 192;
  RCC_OscInitStruct.PLL.PLLP = RCC_PLLP_DIV4;
  RCC_OscInitStruct.PLL.PLLQ = 4;
  RCC_OscInitStruct.PLL.PLLR = 2;
  if (HAL_RCC_OscConfig(&RCC_OscInitStruct) != HAL_OK)
  {
    Error_Handler();
  }

  /** Initializes the CPU, AHB and APB buses clocks
  */
  RCC_ClkInitStruct.ClockType = RCC_CLOCKTYPE_HCLK|RCC_CLOCKTYPE_SYSCLK
                              |RCC_CLOCKTYPE_PCLK1|RCC_CLOCKTYPE_PCLK2;
  RCC_ClkInitStruct.SYSCLKSource = RCC_SYSCLKSOURCE_PLLCLK;
  RCC_ClkInitStruct.AHBCLKDivider = RCC_SYSCLK_DIV1;
  RCC_ClkInitStruct.APB1CLKDivider = RCC_HCLK_DIV4;
  RCC_ClkInitStruct.APB2CLKDivider = RCC_HCLK_DIV2;

  if (HAL_RCC_ClockConfig(&RCC_ClkInitStruct, FLASH_LATENCY_1) != HAL_OK)
  {
    Error_Handler();
  }
}

void PeriphCommonClock_Config(void)
{
  RCC_PeriphCLKInitTypeDef PeriphClkInitStruct = {0};

  /** Initializes the peripherals clock
  */
  PeriphClkInitStruct.PeriphClockSelection = RCC_PERIPHCLK_SAI1|RCC_PERIPHCLK_SAI2
                              |RCC_PERIPHCLK_CLK48;
  PeriphClkInitStruct.PLLSAI.PLLSAIN = 192;
  PeriphClkInitStruct.PLLSAI.PLLSAIR = 2;
  PeriphClkInitStruct.PLLSAI.PLLSAIQ = 3;
  PeriphClkInitStruct.PLLSAI.PLLSAIP = RCC_PLLSAIP_DIV2;
  PeriphClkInitStruct.PLLSAIDivQ = 1;
  PeriphClkInitStruct.PLLSAIDivR = RCC_PLLSAIDIVR_2;
  PeriphClkInitStruct.Sai1ClockSelection = RCC_SAI1CLKSOURCE_PLLSAI;
  PeriphClkInitStruct.Sai2ClockSelection = RCC_SAI2CLKSOURCE_PLLSAI;
  if (HAL_RCCEx_PeriphCLKConfig(&PeriphClkInitStruct) != HAL_OK)
  {
    Error_Handler();
  }
}

static void MX_ADC3_Init(void)
{

  ADC_ChannelConfTypeDef sConfig = {0};

  /** Configure the global features of the ADC (Clock, Resolution, Data Alignment and number of conversion)
  */
  hadc3.Instance = ADC3;
  hadc3.Init.ClockPrescaler = ADC_CLOCK_SYNC_PCLK_DIV2;
  hadc3.Init.Resolution = ADC_RESOLUTION_12B;
  hadc3.Init.ScanConvMode = ADC_SCAN_DISABLE;
  hadc3.Init.ContinuousConvMode = DISABLE;
  hadc3.Init.DiscontinuousConvMode = DISABLE;
  hadc3.Init.ExternalTrigConvEdge = ADC_EXTERNALTRIGCONVEDGE_NONE;
  hadc3.Init.ExternalTrigConv = ADC_SOFTWARE_START;
  hadc3.Init.DataAlign = ADC_DATAALIGN_RIGHT;
  hadc3.Init.NbrOfConversion = 1;
  hadc3.Init.DMAContinuousRequests = DISABLE;
  hadc3.Init.EOCSelection = ADC_EOC_SINGLE_CONV;
  if (HAL_ADC_Init(&hadc3) != HAL_OK)
  {
    Error_Handler();
  }

  /** Configure for the selected ADC regular channel its corresponding rank in the sequencer and its sample time.
  */
  sConfig.Channel = ADC_CHANNEL_8;
  sConfig.Rank = ADC_REGULAR_RANK_1;
  sConfig.SamplingTime = ADC_SAMPLETIME_3CYCLES;
  if (HAL_ADC_ConfigChannel(&hadc3, &sConfig) != HAL_OK)
  {
    Error_Handler();
  }

}

static void MX_DSIHOST_DSI_Init(void)
{

  DSI_PLLInitTypeDef PLLInit = {0};
  DSI_HOST_TimeoutTypeDef HostTimeouts = {0};
  DSI_PHY_TimerTypeDef PhyTimings = {0};
  DSI_LPCmdTypeDef LPCmd = {0};

  hdsi.Instance = DSI;
  hdsi.Init.AutomaticClockLaneControl = DSI_AUTO_CLK_LANE_CTRL_DISABLE;
  hdsi.Init.TXEscapeCkdiv = 4;
  hdsi.Init.NumberOfLanes = DSI_ONE_DATA_LANE;
  PLLInit.PLLNDIV = 20;
  PLLInit.PLLIDF = DSI_PLL_IN_DIV1;
  PLLInit.PLLODF = DSI_PLL_OUT_DIV1;
  if (HAL_DSI_Init(&hdsi, &PLLInit) != HAL_OK)
  {
    Error_Handler();
  }
  HostTimeouts.TimeoutCkdiv = 1;
  HostTimeouts.HighSpeedTransmissionTimeout = 0;
  HostTimeouts.LowPowerReceptionTimeout = 0;
  HostTimeouts.HighSpeedReadTimeout = 0;
  HostTimeouts.LowPowerReadTimeout = 0;
  HostTimeouts.HighSpeedWriteTimeout = 0;
  HostTimeouts.HighSpeedWritePrespMode = DSI_HS_PM_DISABLE;
  HostTimeouts.LowPowerWriteTimeout = 0;
  HostTimeouts.BTATimeout = 0;
  if (HAL_DSI_ConfigHostTimeouts(&hdsi, &HostTimeouts) != HAL_OK)
  {
    Error_Handler();
  }
  PhyTimings.ClockLaneHS2LPTime = 28;
  PhyTimings.ClockLaneLP2HSTime = 33;
  PhyTimings.DataLaneHS2LPTime = 15;
  PhyTimings.DataLaneLP2HSTime = 25;
  PhyTimings.DataLaneMaxReadTime = 0;
  PhyTimings.StopWaitTime = 0;

  if (HAL_DSI_ConfigPhyTimer(&hdsi, &PhyTimings) != HAL_OK)
  {
    Error_Handler();
  }
  if (HAL_DSI_ConfigFlowControl(&hdsi, DSI_FLOW_CONTROL_BTA) != HAL_OK)
  {
    Error_Handler();
  }
  if (HAL_DSI_SetLowPowerRXFilter(&hdsi, 10000) != HAL_OK)
  {
    Error_Handler();
  }
  if (HAL_DSI_ConfigErrorMonitor(&hdsi, HAL_DSI_ERROR_NONE) != HAL_OK)
  {
    Error_Handler();
  }
  LPCmd.LPGenShortWriteNoP = DSI_LP_GSW0P_DISABLE;
  LPCmd.LPGenShortWriteOneP = DSI_LP_GSW1P_DISABLE;
  LPCmd.LPGenShortWriteTwoP = DSI_LP_GSW2P_DISABLE;
  LPCmd.LPGenShortReadNoP = DSI_LP_GSR0P_DISABLE;
  LPCmd.LPGenShortReadOneP = DSI_LP_GSR1P_DISABLE;
  LPCmd.LPGenShortReadTwoP = DSI_LP_GSR2P_DISABLE;
  LPCmd.LPGenLongWrite = DSI_LP_GLW_DISABLE;
  LPCmd.LPDcsShortWriteNoP = DSI_LP_DSW0P_DISABLE;
  LPCmd.LPDcsShortWriteOneP = DSI_LP_DSW1P_DISABLE;
  LPCmd.LPDcsShortReadNoP = DSI_LP_DSR0P_DISABLE;
  LPCmd.LPDcsLongWrite = DSI_LP_DLW_DISABLE;
  LPCmd.LPMaxReadPacket = DSI_LP_MRDP_DISABLE;
  LPCmd.AcknowledgeRequest = DSI_ACKNOWLEDGE_DISABLE;
  if (HAL_DSI_ConfigCommand(&hdsi, &LPCmd) != HAL_OK)
  {
    Error_Handler();
  }

}

static void MX_QUADSPI_Init(void)
{

  /* QUADSPI parameter configuration*/
  hqspi.Instance = QUADSPI;
  hqspi.Init.ClockPrescaler = 1;
  hqspi.Init.FifoThreshold = 4;
  hqspi.Init.SampleShifting = QSPI_SAMPLE_SHIFTING_HALFCYCLE;
  hqspi.Init.FlashSize = 26;
  hqspi.Init.ChipSelectHighTime = QSPI_CS_HIGH_TIME_6_CYCLE;
  hqspi.Init.ClockMode = QSPI_CLOCK_MODE_0;
  hqspi.Init.FlashID = QSPI_FLASH_ID_1;
  hqspi.Init.DualFlash = QSPI_DUALFLASH_DISABLE;
  if (HAL_QSPI_Init(&hqspi) != HAL_OK)
  {
    Error_Handler();
  }

}

static void MX_RTC_Init(void)
{

  RTC_TimeTypeDef sTime = {0};
  RTC_DateTypeDef sDate = {0};

  /** Initialize RTC Only
  */
  hrtc.Instance = RTC;
  hrtc.Init.HourFormat = RTC_HOURFORMAT_24;
  hrtc.Init.AsynchPrediv = 127;
  hrtc.Init.SynchPrediv = 255;
  hrtc.Init.OutPut = RTC_OUTPUT_DISABLE;
  hrtc.Init.OutPutPolarity = RTC_OUTPUT_POLARITY_HIGH;
  hrtc.Init.OutPutType = RTC_OUTPUT_TYPE_OPENDRAIN;
  if (HAL_RTC_Init(&hrtc) != HAL_OK)
  {
    Error_Handler();
  }

  /* USER CODE BEGIN Check_RTC_BKUP */
  //if flag... return
  if (!SET_TIME_RTC)
	  return;

  /* USER CODE END Check_RTC_BKUP */

  /** Initialize RTC and set the Time and Date
  */
  sTime.Hours = 14;
  sTime.Minutes = 14;
  sTime.Seconds = 0x0;
  sTime.DayLightSaving = RTC_DAYLIGHTSAVING_NONE;
  sTime.StoreOperation = RTC_STOREOPERATION_RESET;
  if (HAL_RTC_SetTime(&hrtc, &sTime, RTC_FORMAT_BCD) != HAL_OK)
  {
    Error_Handler();
  }
  sDate.WeekDay = RTC_WEEKDAY_MONDAY;
  sDate.Month = RTC_MONTH_NOVEMBER;
  sDate.Date = 10;
  sDate.Year = 2022;

  if (HAL_RTC_SetDate(&hrtc, &sDate, RTC_FORMAT_BCD) != HAL_OK)
  {
    Error_Handler();
  }

}

static void MX_SAI1_Init(void)
{

  hsai_BlockA1.Instance = SAI1_Block_A;
  hsai_BlockA1.Init.Protocol = SAI_SPDIF_PROTOCOL;
  hsai_BlockA1.Init.AudioMode = SAI_MODEMASTER_TX;
  hsai_BlockA1.Init.Synchro = SAI_ASYNCHRONOUS;
  hsai_BlockA1.Init.OutputDrive = SAI_OUTPUTDRIVE_DISABLE;
  hsai_BlockA1.Init.FIFOThreshold = SAI_FIFOTHRESHOLD_EMPTY;
  hsai_BlockA1.Init.AudioFrequency = SAI_AUDIO_FREQUENCY_48K;
  hsai_BlockA1.Init.MonoStereoMode = SAI_STEREOMODE;
  hsai_BlockA1.Init.CompandingMode = SAI_NOCOMPANDING;
  if (HAL_SAI_Init(&hsai_BlockA1) != HAL_OK)
  {
    Error_Handler();
  }

}

static void MX_SAI2_Init(void)
{

  hsai_BlockB2.Instance = SAI2_Block_B;
  hsai_BlockB2.Init.Protocol = SAI_FREE_PROTOCOL;
  hsai_BlockB2.Init.AudioMode = SAI_MODEMASTER_TX;
  hsai_BlockB2.Init.DataSize = SAI_DATASIZE_8;
  hsai_BlockB2.Init.FirstBit = SAI_FIRSTBIT_MSB;
  hsai_BlockB2.Init.ClockStrobing = SAI_CLOCKSTROBING_FALLINGEDGE;
  hsai_BlockB2.Init.Synchro = SAI_ASYNCHRONOUS;
  hsai_BlockB2.Init.OutputDrive = SAI_OUTPUTDRIVE_DISABLE;
  hsai_BlockB2.Init.NoDivider = SAI_MASTERDIVIDER_ENABLE;
  hsai_BlockB2.Init.FIFOThreshold = SAI_FIFOTHRESHOLD_EMPTY;
  hsai_BlockB2.Init.AudioFrequency = SAI_AUDIO_FREQUENCY_192K;
  hsai_BlockB2.Init.SynchroExt = SAI_SYNCEXT_DISABLE;
  hsai_BlockB2.Init.MonoStereoMode = SAI_STEREOMODE;
  hsai_BlockB2.Init.CompandingMode = SAI_NOCOMPANDING;
  hsai_BlockB2.Init.TriState = SAI_OUTPUT_NOTRELEASED;
  hsai_BlockB2.FrameInit.FrameLength = 8;
  hsai_BlockB2.FrameInit.ActiveFrameLength = 1;
  hsai_BlockB2.FrameInit.FSDefinition = SAI_FS_STARTFRAME;
  hsai_BlockB2.FrameInit.FSPolarity = SAI_FS_ACTIVE_LOW;
  hsai_BlockB2.FrameInit.FSOffset = SAI_FS_FIRSTBIT;
  hsai_BlockB2.SlotInit.FirstBitOffset = 0;
  hsai_BlockB2.SlotInit.SlotSize = SAI_SLOTSIZE_DATASIZE;
  hsai_BlockB2.SlotInit.SlotNumber = 1;
  hsai_BlockB2.SlotInit.SlotActive = 0x00000000;
  if (HAL_SAI_Init(&hsai_BlockB2) != HAL_OK)
  {
    Error_Handler();
  }

}

static void MX_SDMMC1_SD_Init(void)
{

  hsd1.Instance = SDMMC1;
  hsd1.Init.ClockEdge = SDMMC_CLOCK_EDGE_RISING;
  hsd1.Init.ClockBypass = SDMMC_CLOCK_BYPASS_DISABLE;
  hsd1.Init.ClockPowerSave = SDMMC_CLOCK_POWER_SAVE_DISABLE;
  hsd1.Init.BusWide = SDMMC_BUS_WIDE_1B;
  hsd1.Init.HardwareFlowControl = SDMMC_HARDWARE_FLOW_CONTROL_DISABLE;
  hsd1.Init.ClockDiv = 0;

}

static void MX_SPDIFRX_Init(void)
{

  hspdif.Instance = SPDIFRX;
  hspdif.Init.InputSelection = SPDIFRX_INPUT_IN1;
  hspdif.Init.Retries = SPDIFRX_MAXRETRIES_NONE;
  hspdif.Init.WaitForActivity = SPDIFRX_WAITFORACTIVITY_OFF;
  hspdif.Init.ChannelSelection = SPDIFRX_CHANNEL_A;
  hspdif.Init.DataFormat = SPDIFRX_DATAFORMAT_LSB;
  hspdif.Init.StereoMode = SPDIFRX_STEREOMODE_DISABLE;
  hspdif.Init.PreambleTypeMask = SPDIFRX_PREAMBLETYPEMASK_OFF;
  hspdif.Init.ChannelStatusMask = SPDIFRX_CHANNELSTATUS_OFF;
  hspdif.Init.ValidityBitMask = SPDIFRX_VALIDITYMASK_OFF;
  hspdif.Init.ParityErrorMask = SPDIFRX_PARITYERRORMASK_OFF;
  if (HAL_SPDIFRX_Init(&hspdif) != HAL_OK)
  {
    Error_Handler();
  }

}

static void MX_USART1_UART_Init(void)
{

  huart1.Instance = USART1;
  huart1.Init.BaudRate = 115200;
  huart1.Init.WordLength = UART_WORDLENGTH_8B;
  huart1.Init.StopBits = UART_STOPBITS_1;
  huart1.Init.Parity = UART_PARITY_NONE;
  huart1.Init.Mode = UART_MODE_TX_RX;
  huart1.Init.HwFlowCtl = UART_HWCONTROL_NONE;
  huart1.Init.OverSampling = UART_OVERSAMPLING_16;
  huart1.Init.OneBitSampling = UART_ONE_BIT_SAMPLE_DISABLE;
  huart1.AdvancedInit.AdvFeatureInit = UART_ADVFEATURE_NO_INIT;
  if (HAL_UART_Init(&huart1) != HAL_OK)
  {
    Error_Handler();
  }

}

static void MX_USB_OTG_FS_PCD_Init(void)
{

  hpcd_USB_OTG_FS.Instance = USB_OTG_FS;
  hpcd_USB_OTG_FS.Init.dev_endpoints = 6;
  hpcd_USB_OTG_FS.Init.speed = PCD_SPEED_FULL;
  hpcd_USB_OTG_FS.Init.dma_enable = DISABLE;
  hpcd_USB_OTG_FS.Init.phy_itface = PCD_PHY_EMBEDDED;
  hpcd_USB_OTG_FS.Init.Sof_enable = DISABLE;
  hpcd_USB_OTG_FS.Init.low_power_enable = DISABLE;
  hpcd_USB_OTG_FS.Init.lpm_enable = DISABLE;
  hpcd_USB_OTG_FS.Init.vbus_sensing_enable = DISABLE;
  hpcd_USB_OTG_FS.Init.use_dedicated_ep1 = DISABLE;
  if (HAL_PCD_Init(&hpcd_USB_OTG_FS) != HAL_OK)
  {
    Error_Handler();
  }

}

static void MX_DMA_Init(void)
{

  /* DMA controller clock enable */
  __HAL_RCC_DMA2_CLK_ENABLE();

  /* DMA interrupt init */
  /* DMA2_Stream3_IRQn interrupt configuration */
  HAL_NVIC_SetPriority(DMA2_Stream3_IRQn, 0, 0);
  HAL_NVIC_EnableIRQ(DMA2_Stream3_IRQn);
  /* DMA2_Stream6_IRQn interrupt configuration */
  HAL_NVIC_SetPriority(DMA2_Stream6_IRQn, 0, 0);
  HAL_NVIC_EnableIRQ(DMA2_Stream6_IRQn);

}

/* FMC initialization function */
static void MX_FMC_Init(void)
{

  FMC_NORSRAM_TimingTypeDef Timing = {0};
  FMC_SDRAM_TimingTypeDef SdramTiming = {0};

  /** Perform the NOR1 memory initialization sequence
  */
  hnor1.Instance = FMC_NORSRAM_DEVICE;
  hnor1.Extended = FMC_NORSRAM_EXTENDED_DEVICE;
  /* hnor1.Init */
  hnor1.Init.NSBank = FMC_NORSRAM_BANK1;
  hnor1.Init.DataAddressMux = FMC_DATA_ADDRESS_MUX_DISABLE;
  hnor1.Init.MemoryType = FMC_MEMORY_TYPE_NOR;
  hnor1.Init.MemoryDataWidth = FMC_NORSRAM_MEM_BUS_WIDTH_16;
  hnor1.Init.BurstAccessMode = FMC_BURST_ACCESS_MODE_DISABLE;
  hnor1.Init.WaitSignalPolarity = FMC_WAIT_SIGNAL_POLARITY_LOW;
  hnor1.Init.WaitSignalActive = FMC_WAIT_TIMING_BEFORE_WS;
  hnor1.Init.WriteOperation = FMC_WRITE_OPERATION_DISABLE;
  hnor1.Init.WaitSignal = FMC_WAIT_SIGNAL_DISABLE;
  hnor1.Init.ExtendedMode = FMC_EXTENDED_MODE_DISABLE;
  hnor1.Init.AsynchronousWait = FMC_ASYNCHRONOUS_WAIT_ENABLE;
  hnor1.Init.WriteBurst = FMC_WRITE_BURST_DISABLE;
  hnor1.Init.ContinuousClock = FMC_CONTINUOUS_CLOCK_SYNC_ONLY;
  hnor1.Init.WriteFifo = FMC_WRITE_FIFO_ENABLE;
  hnor1.Init.PageSize = FMC_PAGE_SIZE_NONE;
  /* Timing */
  Timing.AddressSetupTime = 15;
  Timing.AddressHoldTime = 15;
  Timing.DataSetupTime = 255;
  Timing.BusTurnAroundDuration = 15;
  Timing.CLKDivision = 16;
  Timing.DataLatency = 17;
  Timing.AccessMode = FMC_ACCESS_MODE_A;
  /* ExtTiming */

  if (HAL_NOR_Init(&hnor1, &Timing, NULL) != HAL_OK)
  {
    Error_Handler( );
  }

  /** Perform the SRAM2 memory initialization sequence
  */
  hsram2.Instance = FMC_NORSRAM_DEVICE;
  hsram2.Extended = FMC_NORSRAM_EXTENDED_DEVICE;
  /* hsram2.Init */
  hsram2.Init.NSBank = FMC_NORSRAM_BANK3;
  hsram2.Init.DataAddressMux = FMC_DATA_ADDRESS_MUX_DISABLE;
  hsram2.Init.MemoryType = FMC_MEMORY_TYPE_SRAM;
  hsram2.Init.MemoryDataWidth = FMC_NORSRAM_MEM_BUS_WIDTH_16;
  hsram2.Init.BurstAccessMode = FMC_BURST_ACCESS_MODE_DISABLE;
  hsram2.Init.WaitSignalPolarity = FMC_WAIT_SIGNAL_POLARITY_LOW;
  hsram2.Init.WaitSignalActive = FMC_WAIT_TIMING_BEFORE_WS;
  hsram2.Init.WriteOperation = FMC_WRITE_OPERATION_DISABLE;
  hsram2.Init.WaitSignal = FMC_WAIT_SIGNAL_DISABLE;
  hsram2.Init.ExtendedMode = FMC_EXTENDED_MODE_DISABLE;
  hsram2.Init.AsynchronousWait = FMC_ASYNCHRONOUS_WAIT_ENABLE;
  hsram2.Init.WriteBurst = FMC_WRITE_BURST_DISABLE;
  hsram2.Init.ContinuousClock = FMC_CONTINUOUS_CLOCK_SYNC_ONLY;
  hsram2.Init.WriteFifo = FMC_WRITE_FIFO_ENABLE;
  hsram2.Init.PageSize = FMC_PAGE_SIZE_NONE;
  /* Timing */
  Timing.AddressSetupTime = 15;
  Timing.AddressHoldTime = 15;
  Timing.DataSetupTime = 255;
  Timing.BusTurnAroundDuration = 15;
  Timing.CLKDivision = 16;
  Timing.DataLatency = 17;
  Timing.AccessMode = FMC_ACCESS_MODE_A;
  /* ExtTiming */

  if (HAL_SRAM_Init(&hsram2, &Timing, NULL) != HAL_OK)
  {
    Error_Handler( );
  }

  /** Perform the SDRAM1 memory initialization sequence
  */
  hsdram1.Instance = FMC_SDRAM_DEVICE;
  /* hsdram1.Init */
  hsdram1.Init.SDBank = FMC_SDRAM_BANK1;
  hsdram1.Init.ColumnBitsNumber = FMC_SDRAM_COLUMN_BITS_NUM_8;
  hsdram1.Init.RowBitsNumber = FMC_SDRAM_ROW_BITS_NUM_13;
  hsdram1.Init.MemoryDataWidth = FMC_SDRAM_MEM_BUS_WIDTH_32;
  hsdram1.Init.InternalBankNumber = FMC_SDRAM_INTERN_BANKS_NUM_4;
  hsdram1.Init.CASLatency = FMC_SDRAM_CAS_LATENCY_1;
  hsdram1.Init.WriteProtection = FMC_SDRAM_WRITE_PROTECTION_DISABLE;
  hsdram1.Init.SDClockPeriod = FMC_SDRAM_CLOCK_DISABLE;
  hsdram1.Init.ReadBurst = FMC_SDRAM_RBURST_DISABLE;
  hsdram1.Init.ReadPipeDelay = FMC_SDRAM_RPIPE_DELAY_0;
  /* SdramTiming */
  SdramTiming.LoadToActiveDelay = 16;
  SdramTiming.ExitSelfRefreshDelay = 16;
  SdramTiming.SelfRefreshTime = 16;
  SdramTiming.RowCycleDelay = 16;
  SdramTiming.WriteRecoveryTime = 16;
  SdramTiming.RPDelay = 16;
  SdramTiming.RCDDelay = 16;

  if (HAL_SDRAM_Init(&hsdram1, &SdramTiming) != HAL_OK)
  {
    Error_Handler( );
  }

}

static void MX_GPIO_Init(void)
{
  GPIO_InitTypeDef GPIO_InitStruct = {0};

  /* GPIO Ports Clock Enable */
  __HAL_RCC_GPIOE_CLK_ENABLE();
  __HAL_RCC_GPIOG_CLK_ENABLE();
  __HAL_RCC_GPIOB_CLK_ENABLE();
  __HAL_RCC_GPIOD_CLK_ENABLE();
  __HAL_RCC_GPIOC_CLK_ENABLE();
  __HAL_RCC_GPIOA_CLK_ENABLE();
  __HAL_RCC_GPIOJ_CLK_ENABLE();
  __HAL_RCC_GPIOI_CLK_ENABLE();
  __HAL_RCC_GPIOK_CLK_ENABLE();
  __HAL_RCC_GPIOF_CLK_ENABLE();
  __HAL_RCC_GPIOH_CLK_ENABLE();

  /*Configure GPIO pin Output Level */
  HAL_GPIO_WritePin(GPIOJ, MII_MDC_GPIO_Pin|MII_MDIO_GPIO_Pin|LED3_Pin|LED1_Pin
                          |LED2_Pin, GPIO_PIN_RESET);

  /*Configure GPIO pin Output Level */
  HAL_GPIO_WritePin(LED0_GPIO_Port, LED0_Pin, GPIO_PIN_RESET);

  /*Configure GPIO pin : MII_TXD3_Pin */
  GPIO_InitStruct.Pin = MII_TXD3_Pin;
  GPIO_InitStruct.Mode = GPIO_MODE_AF_PP;
  GPIO_InitStruct.Pull = GPIO_NOPULL;
  GPIO_InitStruct.Speed = GPIO_SPEED_FREQ_VERY_HIGH;
  GPIO_InitStruct.Alternate = GPIO_AF11_ETH;
  HAL_GPIO_Init(MII_TXD3_GPIO_Port, &GPIO_InitStruct);

  /*Configure GPIO pins : MII_TXD1_Pin MII_TXD0_Pin MII_TX_EN_Pin */
  GPIO_InitStruct.Pin = MII_TXD1_Pin|MII_TXD0_Pin|MII_TX_EN_Pin;
  GPIO_InitStruct.Mode = GPIO_MODE_AF_PP;
  GPIO_InitStruct.Pull = GPIO_NOPULL;
  GPIO_InitStruct.Speed = GPIO_SPEED_FREQ_VERY_HIGH;
  GPIO_InitStruct.Alternate = GPIO_AF11_ETH;
  HAL_GPIO_Init(GPIOG, &GPIO_InitStruct);

  /*Configure GPIO pins : I2C1_SCL_Pin I2C1_SDA_Pin */
  GPIO_InitStruct.Pin = I2C1_SCL_Pin|I2C1_SDA_Pin;
  GPIO_InitStruct.Mode = GPIO_MODE_AF_OD;
  GPIO_InitStruct.Pull = GPIO_NOPULL;
  GPIO_InitStruct.Speed = GPIO_SPEED_FREQ_VERY_HIGH;
  GPIO_InitStruct.Alternate = GPIO_AF4_I2C1;
  HAL_GPIO_Init(GPIOB, &GPIO_InitStruct);

  /*Configure GPIO pins : ULPI_D7_Pin ULPI_D6_Pin ULPI_D5_Pin ULPI_D3_Pin
                           ULPI_D2_Pin ULPI_D4_Pin */
  GPIO_InitStruct.Pin = ULPI_D7_Pin|ULPI_D6_Pin|ULPI_D5_Pin|ULPI_D3_Pin
                          |ULPI_D2_Pin|ULPI_D4_Pin;
  GPIO_InitStruct.Mode = GPIO_MODE_AF_PP;
  GPIO_InitStruct.Pull = GPIO_NOPULL;
  GPIO_InitStruct.Speed = GPIO_SPEED_FREQ_VERY_HIGH;
  GPIO_InitStruct.Alternate = GPIO_AF10_OTG_HS;
  HAL_GPIO_Init(GPIOB, &GPIO_InitStruct);

  /*Configure GPIO pins : SD2_D3_Pin SD2_D2_Pin */
  GPIO_InitStruct.Pin = SD2_D3_Pin|SD2_D2_Pin;
  GPIO_InitStruct.Mode = GPIO_MODE_AF_PP;
  GPIO_InitStruct.Pull = GPIO_NOPULL;
  GPIO_InitStruct.Speed = GPIO_SPEED_FREQ_VERY_HIGH;
  GPIO_InitStruct.Alternate = GPIO_AF10_SDMMC2;
  HAL_GPIO_Init(GPIOB, &GPIO_InitStruct);

  /*Configure GPIO pins : SD2_CMD_Pin SD2_CLK_Pin */
  GPIO_InitStruct.Pin = SD2_CMD_Pin|SD2_CLK_Pin;
  GPIO_InitStruct.Mode = GPIO_MODE_AF_PP;
  GPIO_InitStruct.Pull = GPIO_NOPULL;
  GPIO_InitStruct.Speed = GPIO_SPEED_FREQ_VERY_HIGH;
  GPIO_InitStruct.Alternate = GPIO_AF11_SDMMC2;
  HAL_GPIO_Init(GPIOD, &GPIO_InitStruct);

  /*Configure GPIO pin : PAR_VSYNC_Pin */
  GPIO_InitStruct.Pin = PAR_VSYNC_Pin;
  GPIO_InitStruct.Mode = GPIO_MODE_AF_PP;
  GPIO_InitStruct.Pull = GPIO_NOPULL;
  GPIO_InitStruct.Speed = GPIO_SPEED_FREQ_LOW;
  GPIO_InitStruct.Alternate = GPIO_AF13_DCMI;
  HAL_GPIO_Init(PAR_VSYNC_GPIO_Port, &GPIO_InitStruct);

  /*Configure GPIO pins : MII_MDC_GPIO_Pin MII_MDIO_GPIO_Pin LED3_Pin LED1_Pin
                           LED2_Pin */
  GPIO_InitStruct.Pin = MII_MDC_GPIO_Pin|MII_MDIO_GPIO_Pin|LED3_Pin|LED1_Pin
                          |LED2_Pin;
  GPIO_InitStruct.Mode = GPIO_MODE_OUTPUT_PP;
  GPIO_InitStruct.Pull = GPIO_NOPULL;
  GPIO_InitStruct.Speed = GPIO_SPEED_FREQ_LOW;
  HAL_GPIO_Init(GPIOJ, &GPIO_InitStruct);

  /*Configure GPIO pin : EXPANDER_INT_Pin */
  GPIO_InitStruct.Pin = EXPANDER_INT_Pin;
  GPIO_InitStruct.Mode = GPIO_MODE_IT_RISING;
  GPIO_InitStruct.Pull = GPIO_NOPULL;
  HAL_GPIO_Init(EXPANDER_INT_GPIO_Port, &GPIO_InitStruct);

  /*Configure GPIO pins : LCD_DE_Pin LCD_B7_Pin LCD_B6_Pin LCD_B5_Pin
                           LCD_B4_Pin */
  GPIO_InitStruct.Pin = LCD_DE_Pin|LCD_B7_Pin|LCD_B6_Pin|LCD_B5_Pin
                          |LCD_B4_Pin;
  GPIO_InitStruct.Mode = GPIO_MODE_AF_PP;
  GPIO_InitStruct.Pull = GPIO_NOPULL;
  GPIO_InitStruct.Speed = GPIO_SPEED_FREQ_LOW;
  GPIO_InitStruct.Alternate = GPIO_AF14_LTDC;
  HAL_GPIO_Init(GPIOK, &GPIO_InitStruct);

  /*Configure GPIO pin : SD2_D1_Pin */
  GPIO_InitStruct.Pin = SD2_D1_Pin;
  GPIO_InitStruct.Mode = GPIO_MODE_AF_PP;
  GPIO_InitStruct.Pull = GPIO_NOPULL;
  GPIO_InitStruct.Speed = GPIO_SPEED_FREQ_VERY_HIGH;
  GPIO_InitStruct.Alternate = GPIO_AF11_SDMMC2;
  HAL_GPIO_Init(SD2_D1_GPIO_Port, &GPIO_InitStruct);

  /*Configure GPIO pins : LCD_B2_Pin LCD_B3_Pin LCD_R5_Pin LCD_R6_Pin */
  GPIO_InitStruct.Pin = LCD_B2_Pin|LCD_B3_Pin|LCD_R5_Pin|LCD_R6_Pin;
  GPIO_InitStruct.Mode = GPIO_MODE_AF_PP;
  GPIO_InitStruct.Pull = GPIO_NOPULL;
  GPIO_InitStruct.Speed = GPIO_SPEED_FREQ_LOW;
  GPIO_InitStruct.Alternate = GPIO_AF14_LTDC;
  HAL_GPIO_Init(GPIOJ, &GPIO_InitStruct);

  /*Configure GPIO pin : PAR_D5_Pin */
  GPIO_InitStruct.Pin = PAR_D5_Pin;
  GPIO_InitStruct.Mode = GPIO_MODE_AF_PP;
  GPIO_InitStruct.Pull = GPIO_NOPULL;
  GPIO_InitStruct.Speed = GPIO_SPEED_FREQ_LOW;
  GPIO_InitStruct.Alternate = GPIO_AF13_DCMI;
  HAL_GPIO_Init(PAR_D5_GPIO_Port, &GPIO_InitStruct);

  /*Configure GPIO pin : TAMPER_WKUP_KEY_Pin */
  GPIO_InitStruct.Pin = TAMPER_WKUP_KEY_Pin;
  GPIO_InitStruct.Mode = GPIO_MODE_IT_RISING;
  GPIO_InitStruct.Pull = GPIO_NOPULL;
  HAL_GPIO_Init(TAMPER_WKUP_KEY_GPIO_Port, &GPIO_InitStruct);

  /*Configure GPIO pins : LCD_HSYNC_Pin LCD_VSYNC_Pin LCD_CLK_Pin */
  GPIO_InitStruct.Pin = LCD_HSYNC_Pin|LCD_VSYNC_Pin|LCD_CLK_Pin;
  GPIO_InitStruct.Mode = GPIO_MODE_AF_PP;
  GPIO_InitStruct.Pull = GPIO_NOPULL;
  GPIO_InitStruct.Speed = GPIO_SPEED_FREQ_LOW;
  GPIO_InitStruct.Alternate = GPIO_AF14_LTDC;
  HAL_GPIO_Init(GPIOI, &GPIO_InitStruct);

  /*Configure GPIO pin : ULPI_DIR_Pin */
  GPIO_InitStruct.Pin = ULPI_DIR_Pin;
  GPIO_InitStruct.Mode = GPIO_MODE_AF_PP;
  GPIO_InitStruct.Pull = GPIO_NOPULL;
  GPIO_InitStruct.Speed = GPIO_SPEED_FREQ_VERY_HIGH;
  GPIO_InitStruct.Alternate = GPIO_AF10_OTG_HS;
  HAL_GPIO_Init(ULPI_DIR_GPIO_Port, &GPIO_InitStruct);

  /*Configure GPIO pin : MII_MCO_Pin */
  GPIO_InitStruct.Pin = MII_MCO_Pin;
  GPIO_InitStruct.Mode = GPIO_MODE_AF_PP;
  GPIO_InitStruct.Pull = GPIO_NOPULL;
  GPIO_InitStruct.Speed = GPIO_SPEED_FREQ_LOW;
  GPIO_InitStruct.Alternate = GPIO_AF0_MCO;
  HAL_GPIO_Init(MII_MCO_GPIO_Port, &GPIO_InitStruct);

  /*Configure GPIO pin : LED0_Pin */
  GPIO_InitStruct.Pin = LED0_Pin;
  GPIO_InitStruct.Mode = GPIO_MODE_OUTPUT_PP;
  GPIO_InitStruct.Pull = GPIO_NOPULL;
  GPIO_InitStruct.Speed = GPIO_SPEED_FREQ_LOW;
  HAL_GPIO_Init(LED0_GPIO_Port, &GPIO_InitStruct);

  /*Configure GPIO pin : ULPI_NXT_Pin */
  GPIO_InitStruct.Pin = ULPI_NXT_Pin;
  GPIO_InitStruct.Mode = GPIO_MODE_AF_PP;
  GPIO_InitStruct.Pull = GPIO_NOPULL;
  GPIO_InitStruct.Speed = GPIO_SPEED_FREQ_VERY_HIGH;
  GPIO_InitStruct.Alternate = GPIO_AF10_OTG_HS;
  HAL_GPIO_Init(ULPI_NXT_GPIO_Port, &GPIO_InitStruct);

  /*Configure GPIO pins : MII_TX_CLK_Pin MII_TXD2_Pin MII_RXD0_Pin MII_RXD1_Pin */
  GPIO_InitStruct.Pin = MII_TX_CLK_Pin|MII_TXD2_Pin|MII_RXD0_Pin|MII_RXD1_Pin;
  GPIO_InitStruct.Mode = GPIO_MODE_AF_PP;
  GPIO_InitStruct.Pull = GPIO_NOPULL;
  GPIO_InitStruct.Speed = GPIO_SPEED_FREQ_VERY_HIGH;
  GPIO_InitStruct.Alternate = GPIO_AF11_ETH;
  HAL_GPIO_Init(GPIOC, &GPIO_InitStruct);

  /*Configure GPIO pin : ULPI_STP_Pin */
  GPIO_InitStruct.Pin = ULPI_STP_Pin;
  GPIO_InitStruct.Mode = GPIO_MODE_AF_PP;
  GPIO_InitStruct.Pull = GPIO_NOPULL;
  GPIO_InitStruct.Speed = GPIO_SPEED_FREQ_VERY_HIGH;
  GPIO_InitStruct.Alternate = GPIO_AF10_OTG_HS;
  HAL_GPIO_Init(ULPI_STP_GPIO_Port, &GPIO_InitStruct);

  /*Configure GPIO pins : MII_RX_CLK_Pin MII_RX_DV_Pin */
  GPIO_InitStruct.Pin = MII_RX_CLK_Pin|MII_RX_DV_Pin;
  GPIO_InitStruct.Mode = GPIO_MODE_AF_PP;
  GPIO_InitStruct.Pull = GPIO_NOPULL;
  GPIO_InitStruct.Speed = GPIO_SPEED_FREQ_VERY_HIGH;
  GPIO_InitStruct.Alternate = GPIO_AF11_ETH;
  HAL_GPIO_Init(GPIOA, &GPIO_InitStruct);

  /*Configure GPIO pins : PAR_HSYNC_Pin PAR_PCLK_Pin */
  GPIO_InitStruct.Pin = PAR_HSYNC_Pin|PAR_PCLK_Pin;
  GPIO_InitStruct.Mode = GPIO_MODE_AF_PP;
  GPIO_InitStruct.Pull = GPIO_NOPULL;
  GPIO_InitStruct.Speed = GPIO_SPEED_FREQ_LOW;
  GPIO_InitStruct.Alternate = GPIO_AF13_DCMI;
  HAL_GPIO_Init(GPIOA, &GPIO_InitStruct);

  /*Configure GPIO pins : MII_RXD3_Pin MII_RXD2_Pin */
  GPIO_InitStruct.Pin = MII_RXD3_Pin|MII_RXD2_Pin;
  GPIO_InitStruct.Mode = GPIO_MODE_AF_PP;
  GPIO_InitStruct.Pull = GPIO_NOPULL;
  GPIO_InitStruct.Speed = GPIO_SPEED_FREQ_VERY_HIGH;
  GPIO_InitStruct.Alternate = GPIO_AF11_ETH;
  HAL_GPIO_Init(GPIOH, &GPIO_InitStruct);

  /*Configure GPIO pins : ULPI_CK_Pin ULPI_D0_Pin */
  GPIO_InitStruct.Pin = ULPI_CK_Pin|ULPI_D0_Pin;
  GPIO_InitStruct.Mode = GPIO_MODE_AF_PP;
  GPIO_InitStruct.Pull = GPIO_NOPULL;
  GPIO_InitStruct.Speed = GPIO_SPEED_FREQ_VERY_HIGH;
  GPIO_InitStruct.Alternate = GPIO_AF10_OTG_HS;
  HAL_GPIO_Init(GPIOA, &GPIO_InitStruct);

  /*Configure GPIO pins : JOY_SEL_Pin PB15 */
  GPIO_InitStruct.Pin = JOY_SEL_Pin|GPIO_PIN_15;
  GPIO_InitStruct.Mode = GPIO_MODE_INPUT;
  GPIO_InitStruct.Pull = GPIO_NOPULL;
  HAL_GPIO_Init(GPIOB, &GPIO_InitStruct);

  /*Configure GPIO pin : USB_FS2_DM_Pin */
  GPIO_InitStruct.Pin = USB_FS2_DM_Pin;
  GPIO_InitStruct.Mode = GPIO_MODE_AF_PP;
  GPIO_InitStruct.Pull = GPIO_NOPULL;
  GPIO_InitStruct.Speed = GPIO_SPEED_FREQ_VERY_HIGH;
  GPIO_InitStruct.Alternate = GPIO_AF12_OTG_HS_FS;
  HAL_GPIO_Init(USB_FS2_DM_GPIO_Port, &GPIO_InitStruct);

}

void Error_Handler(void)
{
  __disable_irq();
  while (1)
  {
  }
}
